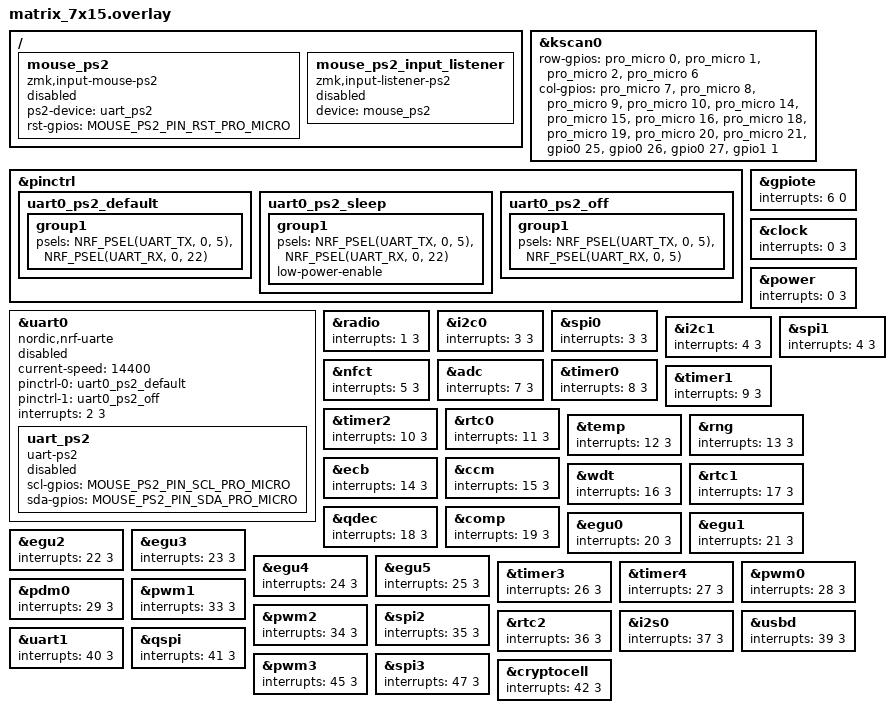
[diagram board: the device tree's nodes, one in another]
/*
 * 7x15 矩阵键盘 - nice!nano 引脚（row2col）
 * 以下与 ZMK app/module/boards/nicekeyboards/nice_nano/arduino_pro_micro_pins.dtsi 一致。
 *
 * row（输出）7 个 — 板子标号 → 芯片引脚:
 *   row0  pro_micro 0   D0   →  P0.8
 *   row1  pro_micro 1   D1   →  P0.6
 *   row2  pro_micro 2   D2   →  P0.17
 *   row3  pro_micro 3   D3   →  P0.20
 *   row4  pro_micro 4   D4   →  P0.22
 *   row5  pro_micro 5   D5   →  P0.24
 *   row6  pro_micro 6   D6   →  P1.0
 *
 * col（输入）15 个:
 *   col0   pro_micro 7   D7   →  P0.11
 *   col1   pro_micro 8   D8   →  P1.4
 *   col2   pro_micro 9   D9   →  P1.6
 *   col3   pro_micro 10  D10  →  P0.9
 *   col4   pro_micro 14  D14  →  P1.11
 *   col5   pro_micro 15  D15  →  P1.13
 *   col6   pro_micro 16  D16  →  P0.10
 *   col7   pro_micro 18  D18/A0 → P1.15
 *   col8   pro_micro 19  D19/A1 → P0.2
 *   col9   pro_micro 20  D20/A2 → P0.29  (部分板子用作 USB，慎用)
 *   col10  pro_micro 21  D21/A3 → P0.31
 *   col11  gpio0 25     →  P0.25  (需核对板子是否引出)
 *   col12  gpio0 26     →  P0.26  (需核对板子是否引出)
 *   col13  gpio0 27     →  P0.27  (需核对板子是否引出)
 *   col14  gpio1 1      →  P1.1   (需核对板子是否引出)
 *
 * 电平（实测）: 接 row 后 不按=0V、按下=110mV，两者都低无法区分。
 * 改为：扫描时 row 输出高（3.3V），col 下拉；不按=0V（低），按下=col 接到 row 高≈3.3V（高），即可区分。
 * SPDX-License-Identifier: MIT
 */

#include "matrix_7x15.dtsi"

&kscan0 {
    /* 4 行：row3/4/5 的 020/022/024 给小红点用 */
    row-gpios
        = <&pro_micro 0 GPIO_ACTIVE_HIGH>
        , <&pro_micro 1 GPIO_ACTIVE_HIGH>
        , <&pro_micro 2 GPIO_ACTIVE_HIGH>
        , <&pro_micro 6 GPIO_ACTIVE_HIGH>
        ;

    /* col 下拉；不按=0V（低），按下=读到高（3.3V） */
    col-gpios
        = <&pro_micro 7  (GPIO_ACTIVE_HIGH | GPIO_PULL_DOWN)>
        , <&pro_micro 8  (GPIO_ACTIVE_HIGH | GPIO_PULL_DOWN)>
        , <&pro_micro 9  (GPIO_ACTIVE_HIGH | GPIO_PULL_DOWN)>
        , <&pro_micro 10 (GPIO_ACTIVE_HIGH | GPIO_PULL_DOWN)>
        , <&pro_micro 14 (GPIO_ACTIVE_HIGH | GPIO_PULL_DOWN)>
        , <&pro_micro 15 (GPIO_ACTIVE_HIGH | GPIO_PULL_DOWN)>
        , <&pro_micro 16 (GPIO_ACTIVE_HIGH | GPIO_PULL_DOWN)>
        , <&pro_micro 18 (GPIO_ACTIVE_HIGH | GPIO_PULL_DOWN)>
        , <&pro_micro 19 (GPIO_ACTIVE_HIGH | GPIO_PULL_DOWN)>
        , <&pro_micro 20 (GPIO_ACTIVE_HIGH | GPIO_PULL_DOWN)>
        , <&pro_micro 21 (GPIO_ACTIVE_HIGH | GPIO_PULL_DOWN)>
        , <&gpio0 25 (GPIO_ACTIVE_HIGH | GPIO_PULL_DOWN)>
        , <&gpio0 26 (GPIO_ACTIVE_HIGH | GPIO_PULL_DOWN)>
        , <&gpio0 27 (GPIO_ACTIVE_HIGH | GPIO_PULL_DOWN)>
        , <&gpio1 1  (GPIO_ACTIVE_HIGH | GPIO_PULL_DOWN)>
        ;
};

/*
 * ThinkPad 小红点 (PS/2 TrackPoint) — 仅用 024 / 022 / 020
 * 020 = P0.20 = D3 = pro_micro 3 = RST
 * 022 = P0.22 = D4 = pro_micro 4 = SDA
 * 024 = P0.24 = D5 = pro_micro 5 = SCL
 */
#define MOUSE_PS2_DRIVER_UART
#define MOUSE_PS2_PIN_SCL_PRO_MICRO <&pro_micro 5 GPIO_ACTIVE_HIGH>
#define MOUSE_PS2_PIN_SDA_PRO_MICRO <&pro_micro 4 GPIO_ACTIVE_HIGH>
#define MOUSE_PS2_PIN_SDA_PINCTRL NRF_PSEL(UART_RX, 0, 22)
#define MOUSE_PS2_PIN_RST_PRO_MICRO <&pro_micro 3 GPIO_ACTIVE_HIGH>
#define MOUSE_PS2_UART_BAUD_RATE 14400
#define MOUSE_PS2_DT_PRESENT

&pinctrl {
    /* UART TX 用未引出引脚；RX = SDA = P0.22 */
    uart0_ps2_default: uart0_ps2_default {
        group1 {
            psels = <NRF_PSEL(UART_TX, 0, 5)>,
                    <NRF_PSEL(UART_RX, 0, 22)>;
        };
    };
    uart0_ps2_sleep: uart0_ps2_sleep {
        group1 {
            psels = <NRF_PSEL(UART_TX, 0, 5)>,
                    <NRF_PSEL(UART_RX, 0, 22)>;
            low-power-enable;
        };
    };
    uart0_ps2_off: uart0_ps2_off {
        group1 {
            psels = <NRF_PSEL(UART_TX, 0, 5)>,
                    <NRF_PSEL(UART_RX, 0, 5)>;
        };
    };
};

&uart0 {
    status = "disabled";
    compatible = "nordic,nrf-uarte";
    current-speed = <14400>;
    pinctrl-0 = <&uart0_ps2_default>;
    pinctrl-1 = <&uart0_ps2_off>;
    pinctrl-names = "default", "sleep";
    uart_ps2: uart_ps2 {
        status = "disabled";
        compatible = "uart-ps2";
        scl-gpios = MOUSE_PS2_PIN_SCL_PRO_MICRO;
        sda-gpios = MOUSE_PS2_PIN_SDA_PRO_MICRO;
    };
};

/ {
    mouse_ps2: mouse_ps2 {
        status = "disabled";
        compatible = "zmk,input-mouse-ps2";
        ps2-device = <&uart_ps2>;
        rst-gpios = MOUSE_PS2_PIN_RST_PRO_MICRO;
    };
    mouse_ps2_input_listener: mouse_ps2_input_listener {
        compatible = "zmk,input-listener-ps2";
        status = "disabled";
        device = <&mouse_ps2>;
    };
};

/* PS/2 中断优先级：gpiote 最高，其余降低，避免丢包 */
&gpiote { interrupts = < 6 0 >; };
&clock { interrupts = < 0 3 >; };
&power { interrupts = < 0 3 >; };
&radio { interrupts = < 1 3 >; };
&uart0 { interrupts = < 2 3 >; };
&i2c0 { interrupts = < 3 3 >; };
&spi0 { interrupts = < 3 3 >; };
&i2c1 { interrupts = < 4 3 >; };
&spi1 { interrupts = < 4 3 >; };
&nfct { interrupts = < 5 3 >; };
&adc { interrupts = < 7 3 >; };
&timer0 { interrupts = < 8 3 >; };
&timer1 { interrupts = < 9 3 >; };
&timer2 { interrupts = < 10 3 >; };
&rtc0 { interrupts = < 11 3 >; };
&temp { interrupts = < 12 3 >; };
&rng { interrupts = < 13 3 >; };
&ecb { interrupts = < 14 3 >; };
&ccm { interrupts = < 15 3 >; };
&wdt { interrupts = < 16 3 >; };
&rtc1 { interrupts = < 17 3 >; };
&qdec { interrupts = < 18 3 >; };
&comp { interrupts = < 19 3 >; };
&egu0 { interrupts = < 20 3 >; };
&egu1 { interrupts = < 21 3 >; };
&egu2 { interrupts = < 22 3 >; };
&egu3 { interrupts = < 23 3 >; };
&egu4 { interrupts = < 24 3 >; };
&egu5 { interrupts = < 25 3 >; };
&timer3 { interrupts = < 26 3 >; };
&timer4 { interrupts = < 27 3 >; };
&pwm0 { interrupts = < 28 3 >; };
&pdm0 { interrupts = < 29 3 >; };
&pwm1 { interrupts = < 33 3 >; };
&pwm2 { interrupts = < 34 3 >; };
&spi2 { interrupts = < 35 3 >; };
&rtc2 { interrupts = < 36 3 >; };
&i2s0 { interrupts = < 37 3 >; };
&usbd { interrupts = < 39 3 >; };
&uart1 { interrupts = < 40 3 >; };
&qspi { interrupts = < 41 3 >; };
&pwm3 { interrupts = < 45 3 >; };
&spi3 { interrupts = < 47 3 >; };
&cryptocell { interrupts = < 42 3 >; };
